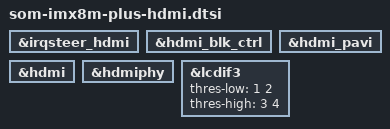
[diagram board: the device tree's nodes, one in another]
&irqsteer_hdmi {
	status = "okay";
};

&hdmi_blk_ctrl {
	status = "okay";
};

&hdmi_pavi {
	status = "okay";
};

&hdmi {
	status = "okay";
};

&hdmiphy {
	status = "okay";
};

&lcdif3 {
	status = "okay";

	thres-low  = <1 2>;             /* (FIFO * 1 / 2) */
	thres-high = <3 4>;             /* (FIFO * 3 / 4) */
};
